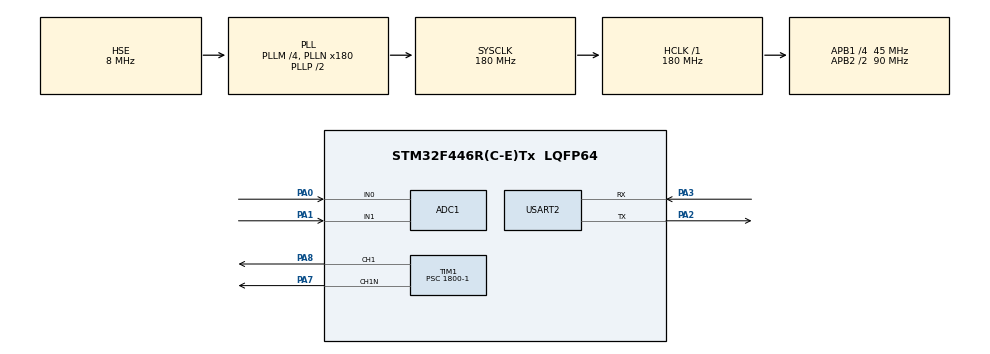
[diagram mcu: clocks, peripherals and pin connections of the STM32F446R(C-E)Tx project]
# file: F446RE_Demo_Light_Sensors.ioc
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ADC1.Channel-0\#ChannelRegularConversion=ADC_CHANNEL_0
ADC1.Channel-1\#ChannelRegularConversion=ADC_CHANNEL_1
ADC1.DMAContinuousRequests=ENABLE
ADC1.EOCSelection=ADC_EOC_SEQ_CONV
ADC1.ExternalTrigConv=ADC_EXTERNALTRIGCONV_T2_TRGO
ADC1.NbrOfConversion=2
ADC1.NbrOfConversionFlag=1
ADC1.Rank-0\#ChannelRegularConversion=1
ADC1.Rank-1\#ChannelRegularConversion=2
ADC1.SamplingTime-0\#ChannelRegularConversion=ADC_SAMPLETIME_3CYCLES
ADC1.SamplingTime-1\#ChannelRegularConversion=ADC_SAMPLETIME_3CYCLES
ADC1.master=1
Dma.ADC1.0.Direction=DMA_PERIPH_TO_MEMORY
Dma.ADC1.0.FIFOMode=DMA_FIFOMODE_DISABLE
Dma.ADC1.0.Instance=DMA2_Stream0
Dma.ADC1.0.MemDataAlignment=DMA_MDATAALIGN_HALFWORD
Dma.ADC1.0.MemInc=DMA_MINC_ENABLE
Dma.ADC1.0.Mode=DMA_CIRCULAR
Dma.ADC1.0.PeriphDataAlignment=DMA_PDATAALIGN_HALFWORD
Dma.ADC1.0.PeriphInc=DMA_PINC_DISABLE
Dma.ADC1.0.Priority=DMA_PRIORITY_LOW
Dma.Request0=ADC1
Dma.Request1=TIM1_CH1
Dma.Request2=USART2_TX
Dma.TIM1_CH1.1.Direction=DMA_MEMORY_TO_PERIPH
Dma.TIM1_CH1.1.FIFOMode=DMA_FIFOMODE_DISABLE
Dma.TIM1_CH1.1.Instance=DMA2_Stream1
Dma.TIM1_CH1.1.MemDataAlignment=DMA_MDATAALIGN_HALFWORD
Dma.TIM1_CH1.1.MemInc=DMA_MINC_ENABLE
Dma.TIM1_CH1.1.Mode=DMA_CIRCULAR
Dma.TIM1_CH1.1.PeriphDataAlignment=DMA_PDATAALIGN_HALFWORD
Dma.TIM1_CH1.1.PeriphInc=DMA_PINC_DISABLE
Dma.TIM1_CH1.1.Priority=DMA_PRIORITY_LOW
Dma.USART2_TX.2.Direction=DMA_MEMORY_TO_PERIPH
Dma.USART2_TX.2.FIFOMode=DMA_FIFOMODE_DISABLE
Dma.USART2_TX.2.Instance=DMA1_Stream6
Dma.USART2_TX.2.MemDataAlignment=DMA_MDATAALIGN_BYTE
Dma.USART2_TX.2.MemInc=DMA_MINC_ENABLE
Dma.USART2_TX.2.Mode=DMA_CIRCULAR
Dma.USART2_TX.2.PeriphDataAlignment=DMA_PDATAALIGN_BYTE
Dma.USART2_TX.2.PeriphInc=DMA_PINC_DISABLE
Dma.USART2_TX.2.Priority=DMA_PRIORITY_LOW
Mcu.Family=STM32F4
Mcu.Name=STM32F446R(C-E)Tx
Mcu.Package=LQFP64
NVIC.ADC_IRQn=true\:0\:0\:false\:false\:true\:true\:true\:true
NVIC.DMA1_Stream6_IRQn=true\:0\:0\:false\:false\:true\:false\:true\:true
NVIC.DMA2_Stream0_IRQn=true\:0\:0\:false\:false\:true\:false\:true\:true
NVIC.DMA2_Stream1_IRQn=true\:0\:0\:false\:false\:true\:false\:true\:true
NVIC.PriorityGroup=NVIC_PRIORITYGROUP_4
NVIC.TIM2_IRQn=true\:0\:0\:false\:false\:true\:true\:true\:true
NVIC.USART2_IRQn=true\:0\:0\:false\:false\:true\:true\:true\:true
PA0-WKUP.Signal=ADCx_IN0
PA1.Signal=ADCx_IN1
PA13.Mode=Serial_Wire
PA13.Signal=SYS_JTMS-SWDIO
PA14.Mode=Serial_Wire
PA14.Signal=SYS_JTCK-SWCLK
PA2.Mode=Asynchronous
PA2.Signal=USART2_TX
PA3.Mode=Asynchronous
PA3.Signal=USART2_RX
PA7.Mode=PWM Generation1 CH1 CH1N
PA7.Signal=TIM1_CH1N
PA8.Signal=S_TIM1_CH1
PH0-OSC_IN.Mode=HSE-External-Clock-Source
PH0-OSC_IN.Signal=RCC_OSC_IN
PH1-OSC_OUT.Mode=HSE-External-Clock-Source
PH1-OSC_OUT.Signal=RCC_OSC_OUT
ProjectManager.HeapSize=0x200
ProjectManager.StackSize=0x400
ProjectManager.TargetToolchain=STM32CubeIDE
RCC.AHBFreq_Value=180000000
RCC.APB1CLKDivider=RCC_HCLK_DIV4
RCC.APB1Freq_Value=45000000
RCC.APB1TimFreq_Value=90000000
RCC.APB2CLKDivider=RCC_HCLK_DIV2
RCC.APB2Freq_Value=90000000
RCC.APB2TimFreq_Value=180000000
RCC.CortexFreq_Value=180000000
RCC.HCLKFreq_Value=180000000
RCC.HSE_VALUE=8000000
RCC.PLLM=4
RCC.PLLN=180
RCC.PLLSourceVirtual=RCC_PLLSOURCE_HSE
RCC.SYSCLKFreq_VALUE=180000000
RCC.SYSCLKSource=RCC_SYSCLKSOURCE_PLLCLK
RCC.USBFreq_Value=180000000
RCC.VCOOutputFreq_Value=360000000
SH.ADCx_IN0.0=ADC1_IN0,IN0
SH.ADCx_IN1.0=ADC1_IN1,IN1
SH.S_TIM1_CH1.0=TIM1_CH1,PWM Generation1 CH1 CH1N
TIM1.Channel-PWM\ Generation1\ CH1\ CH1N=TIM_CHANNEL_1
TIM1.OCNPolarity_1=TIM_OCNPOLARITY_HIGH
TIM1.Period=1000-1
TIM1.Prescaler=1800-1
TIM2.Period=1000-1
TIM2.Prescaler=900-1
TIM2.TIM_MasterOutputTrigger=TIM_TRGO_UPDATE
USART2.VirtualMode=VM_ASYNC
VP_TIM1_VS_ClockSourceINT.Mode=Internal
VP_TIM2_VS_ClockSourceINT.Mode=Internal
board=custom

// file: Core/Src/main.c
/* USER CODE BEGIN Header */
/**
  ******************************************************************************
  * @file           : main.c
  * @brief          : Main program body
  ******************************************************************************
  * @attention
  *
  * Copyright (c) 2026 STMicroelectronics.
  * All rights reserved.
  *
  * This software is licensed under terms that can be found in the LICENSE file
  * in the root directory of this software component.
  * If no LICENSE file comes with this software, it is provided AS-IS.
  *
  ******************************************************************************
  */
/* USER CODE END Header */
#include "main.h"

/* USER CODE BEGIN Includes */
#include <stdio.h>
#include <string.h>
/* USER CODE END Includes */

/* USER CODE BEGIN PD */
#define ADC_BUF_LEN 40	//set adc buffer size
/* USER CODE END PD */

ADC_HandleTypeDef hadc1;
DMA_HandleTypeDef hdma_adc1;

TIM_HandleTypeDef htim1;
TIM_HandleTypeDef htim2;
DMA_HandleTypeDef hdma_tim1_ch1;

UART_HandleTypeDef huart2;
DMA_HandleTypeDef hdma_usart2_tx;

void SystemClock_Config(void);
static void MX_GPIO_Init(void);
static void MX_DMA_Init(void);
static void MX_ADC1_Init(void);
static void MX_TIM2_Init(void);
static void MX_TIM1_Init(void);
static void MX_USART2_UART_Init(void);

/* USER CODE BEGIN 0 */

// Pre-computed 512-point sine wave scaled for ARR = 1000
const uint16_t SINE_WAVE_LUT_512[512] = {
     500,  506,  512,  518,  525,  531,  537,  543,  549,  555,  561,  567,  573,  579,  585,  592,
     598,  604,  610,  616,  621,  627,  633,  639,  645,  651,  657,  663,  668,  674,  680,  686,
     691,  697,  703,  708,  714,  719,  725,  730,  736,  741,  746,  752,  757,  762,  767,  773,
     778,  783,  788,  793,  798,  803,  808,  812,  817,  822,  827,  831,  836,  840,  845,  849,
     854,  858,  862,  866,  870,  875,  879,  883,  887,  890,  894,  898,  902,  905,  909,  912,
     916,  919,  922,  926,  929,  932,  935,  938,  941,  944,  947,  949,  952,  955,  957,  960,
     962,  964,  966,  969,  971,  973,  975,  977,  978,  980,  982,  983,  985,  986,  988,  989,
     990,  992,  993,  994,  995,  995,  996,  997,  998,  998,  999,  999,  999, 1000, 1000, 1000,
    1000, 1000, 1000, 1000,  999,  999,  999,  998,  998,  997,  996,  995,  995,  994,  993,  992,
     990,  989,  988,  986,  985,  983,  982,  980,  978,  977,  975,  973,  971,  969,  966,  964,
     962,  960,  957,  955,  952,  949,  947,  944,  941,  938,  935,  932,  929,  926,  922,  919,
     916,  912,  909,  905,  902,  898,  894,  890,  887,  883,  879,  875,  870,  866,  862,  858,
     854,  849,  845,  840,  836,  831,  827,  822,  817,  812,  808,  803,  798,  793,  788,  783,
     778,  773,  767,  762,  757,  752,  746,  741,  736,  730,  725,  719,  714,  708,  703,  697,
     691,  686,  680,  674,  668,  663,  657,  651,  645,  639,  633,  627,  621,  616,  610,  604,
     598,  592,  585,  579,  573,  567,  561,  555,  549,  543,  537,  531,  525,  518,  512,  506,
     500,  494,  488,  482,  475,  469,  463,  457,  451,  445,  439,  433,  427,  421,  415,  408,
     402,  396,  390,  384,  379,  373,  367,  361,  355,  349,  343,  337,  332,  326,  320,  314,
     309,  303,  297,  292,  286,  281,  275,  270,  264,  259,  254,  248,  243,  238,  233,  227,
     222,  217,  212,  207,  202,  197,  192,  188,  183,  178,  173,  169,  164,  160,  155,  151,
     146,  142,  138,  134,  130,  125,  121,  117,  113,  110,  106,  102,   98,   95,   91,   88,
      84,   81,   78,   74,   71,   68,   65,   62,   59,   56,   53,   51,   48,   45,   43,   40,
      38,   36,   34,   31,   29,   27,   25,   23,   22,   20,   18,   17,   15,   14,   12,   11,
      10,    8,    7,    6,    5,    5,    4,    3,    2,    2,    1,    1,    1,    0,    0,    0,
       0,    0,    0,    0,    1,    1,    1,    2,    2,    3,    4,    5,    5,    6,    7,    8,
      10,   11,   12,   14,   15,   17,   18,   20,   22,   23,   25,   27,   29,   31,   34,   36,
      38,   40,   43,   45,   48,   51,   53,   56,   59,   62,   65,   68,   71,   74,   78,   81,
      84,   88,   91,   95,   98,  102,  106,  110,  113,  117,  121,  125,  130,  134,  138,  142,
     146,  151,  155,  160,  164,  169,  173,  178,  183,  188,  192,  197,  202,  207,  212,  217,
     222,  227,  233,  238,  243,  248,  254,  259,  264,  270,  275,  281,  286,  292,  297,  303,
     309,  314,  320,  326,  332,  337,  343,  349,  355,  361,  367,  373,  379,  384,  390,  396,
     402,  408,  415,  421,  427,  433,  439,  445,  451,  457,  463,  469,  475,  482,  488,  494
};

uint16_t ADCBatchData[ADC_BUF_LEN];	//store the 2 channels raw ADC data in a batch of 20 samples (40 elements)
char uartTxBuffer[256];	//store the formatted ADC data to transmit via uart, 256 bytes big enough to temporarily hold the formatted 10 samples

//helper function to format the raw adc data and store into uartTxBuffer, then transmit the half buffer
//param: half of the adc buffer = ADCBatchData[0] or ADCBatchData[20]
void processADCData(uint16_t* half_buffer)
{

    uartTxBuffer[0] = '\0';	//Clear the tx buffer
    char temp[32];	//temp buffer to format and move ADC data into the main tx buffer

    //format and load the adc data to the main tx buffer
    for(int i = 0; i < (ADC_BUF_LEN / 2); i += 2)
    {
    	//load raw ADC data
        uint16_t adcDataC1 = half_buffer[i];		//channel 1
        uint16_t adcDataC2 = half_buffer[i + 1];	//channel 2

        //format the datas and store to temp, then temp cocantenate it to the main tx buffer
        sprintf(temp, "%u, %u \r\n", adcDataC1, adcDataC2);
        strcat(uartTxBuffer, temp);	//strcat() appends a copy of one string to the end of another
    }

    //transmit the formatted data
    HAL_UART_Transmit_DMA(&huart2, (uint8_t*)uartTxBuffer, strlen(uartTxBuffer));
}

void HAL_ADC_ConvHalfCpltCallback(ADC_HandleTypeDef *hadc)
{
	processADCData(&ADCBatchData[0]);	//process and tx first half of the ADC data
}

void HAL_ADC_ConvCpltCallback(ADC_HandleTypeDef *hadc)
{
	processADCData(&ADCBatchData[ADC_BUF_LEN / 2]);	//process and tx 2nd half of the ADC data
}

/* USER CODE END 0 */

int main(void)
{

  /* MCU Configuration--------------------------------------------------------*/

  /* Reset of all peripherals, Initializes the Flash interface and the Systick. */
  HAL_Init();

  /* Configure the system clock */
  SystemClock_Config();

  /* Initialize all configured peripherals */
  MX_GPIO_Init();
  MX_DMA_Init();
  MX_ADC1_Init();
  MX_TIM2_Init();
  MX_TIM1_Init();
  MX_USART2_UART_Init();
  /* USER CODE BEGIN 2 */

  HAL_TIM_Base_Start(&htim2);	//start timer2 as per configured
  HAL_ADC_Start_DMA(&hadc1, (uint32_t *)ADCBatchData, ADC_BUF_LEN);	//ADC sampling rate = 100Hz, uart baudrate 115200

  //generate sine wave blue led f_sine = 100Hz/512 = 0.195Hz, tim1 freq = 100 Hz
  HAL_TIM_PWM_Start_DMA(&htim1, TIM_CHANNEL_1, (uint32_t *)SINE_WAVE_LUT_512, 512);
  //generate cos wave via Complementary Output "PWM Generation CH1 CH1N" mode
  HAL_TIMEx_PWMN_Start(&htim1, TIM_CHANNEL_1);

  /* USER CODE END 2 */

  /* Infinite loop */
  while (1)
  {

  }
}

void SystemClock_Config(void)
{
  RCC_OscInitTypeDef RCC_OscInitStruct = {0};
  RCC_ClkInitTypeDef RCC_ClkInitStruct = {0};

  /** Configure the main internal regulator output voltage
  */
  __HAL_RCC_PWR_CLK_ENABLE();
  __HAL_PWR_VOLTAGESCALING_CONFIG(PWR_REGULATOR_VOLTAGE_SCALE1);

  /** Initializes the RCC Oscillators according to the specified parameters
  * in the RCC_OscInitTypeDef structure.
  */
  RCC_OscInitStruct.OscillatorType = RCC_OSCILLATORTYPE_HSE;
  RCC_OscInitStruct.HSEState = RCC_HSE_BYPASS;
  RCC_OscInitStruct.PLL.PLLState = RCC_PLL_ON;
  RCC_OscInitStruct.PLL.PLLSource = RCC_PLLSOURCE_HSE;
  RCC_OscInitStruct.PLL.PLLM = 4;
  RCC_OscInitStruct.PLL.PLLN = 180;
  RCC_OscInitStruct.PLL.PLLP = RCC_PLLP_DIV2;
  RCC_OscInitStruct.PLL.PLLQ = 2;
  RCC_OscInitStruct.PLL.PLLR = 2;
  if (HAL_RCC_OscConfig(&RCC_OscInitStruct) != HAL_OK)
  {
    Error_Handler();
  }

  /** Activate the Over-Drive mode
  */
  if (HAL_PWREx_EnableOverDrive() != HAL_OK)
  {
    Error_Handler();
  }

  /** Initializes the CPU, AHB and APB buses clocks
  */
  RCC_ClkInitStruct.ClockType = RCC_CLOCKTYPE_HCLK|RCC_CLOCKTYPE_SYSCLK
                              |RCC_CLOCKTYPE_PCLK1|RCC_CLOCKTYPE_PCLK2;
  RCC_ClkInitStruct.SYSCLKSource = RCC_SYSCLKSOURCE_PLLCLK;
  RCC_ClkInitStruct.AHBCLKDivider = RCC_SYSCLK_DIV1;
  RCC_ClkInitStruct.APB1CLKDivider = RCC_HCLK_DIV4;
  RCC_ClkInitStruct.APB2CLKDivider = RCC_HCLK_DIV2;

  if (HAL_RCC_ClockConfig(&RCC_ClkInitStruct, FLASH_LATENCY_5) != HAL_OK)
  {
    Error_Handler();
  }
}

static void MX_ADC1_Init(void)
{

  ADC_ChannelConfTypeDef sConfig = {0};

  /** Configure the global features of the ADC (Clock, Resolution, Data Alignment and number of conversion)
  */
  hadc1.Instance = ADC1;
  hadc1.Init.ClockPrescaler = ADC_CLOCK_SYNC_PCLK_DIV4;
  hadc1.Init.Resolution = ADC_RESOLUTION_12B;
  hadc1.Init.ScanConvMode = ENABLE;
  hadc1.Init.ContinuousConvMode = DISABLE;
  hadc1.Init.DiscontinuousConvMode = DISABLE;
  hadc1.Init.ExternalTrigConvEdge = ADC_EXTERNALTRIGCONVEDGE_RISING;
  hadc1.Init.ExternalTrigConv = ADC_EXTERNALTRIGCONV_T2_TRGO;
  hadc1.Init.DataAlign = ADC_DATAALIGN_RIGHT;
  hadc1.Init.NbrOfConversion = 2;
  hadc1.Init.DMAContinuousRequests = ENABLE;
  hadc1.Init.EOCSelection = ADC_EOC_SEQ_CONV;
  if (HAL_ADC_Init(&hadc1) != HAL_OK)
  {
    Error_Handler();
  }

  /** Configure for the selected ADC regular channel its corresponding rank in the sequencer and its sample time.
  */
  sConfig.Channel = ADC_CHANNEL_0;
  sConfig.Rank = 1;
  sConfig.SamplingTime = ADC_SAMPLETIME_3CYCLES;
  if (HAL_ADC_ConfigChannel(&hadc1, &sConfig) != HAL_OK)
  {
    Error_Handler();
  }

  /** Configure for the selected ADC regular channel its corresponding rank in the sequencer and its sample time.
  */
  sConfig.Channel = ADC_CHANNEL_1;
  sConfig.Rank = 2;
  if (HAL_ADC_ConfigChannel(&hadc1, &sConfig) != HAL_OK)
  {
    Error_Handler();
  }

}

static void MX_TIM1_Init(void)
{

  TIM_ClockConfigTypeDef sClockSourceConfig = {0};
  TIM_MasterConfigTypeDef sMasterConfig = {0};
  TIM_OC_InitTypeDef sConfigOC = {0};
  TIM_BreakDeadTimeConfigTypeDef sBreakDeadTimeConfig = {0};

  htim1.Instance = TIM1;
  htim1.Init.Prescaler = 1800-1;
  htim1.Init.CounterMode = TIM_COUNTERMODE_UP;
  htim1.Init.Period = 1000-1;
  htim1.Init.ClockDivision = TIM_CLOCKDIVISION_DIV1;
  htim1.Init.RepetitionCounter = 0;
  htim1.Init.AutoReloadPreload = TIM_AUTORELOAD_PRELOAD_DISABLE;
  if (HAL_TIM_Base_Init(&htim1) != HAL_OK)
  {
    Error_Handler();
  }
  sClockSourceConfig.ClockSource = TIM_CLOCKSOURCE_INTERNAL;
  if (HAL_TIM_ConfigClockSource(&htim1, &sClockSourceConfig) != HAL_OK)
  {
    Error_Handler();
  }
  if (HAL_TIM_PWM_Init(&htim1) != HAL_OK)
  {
    Error_Handler();
  }
  sMasterConfig.MasterOutputTrigger = TIM_TRGO_RESET;
  sMasterConfig.MasterSlaveMode = TIM_MASTERSLAVEMODE_DISABLE;
  if (HAL_TIMEx_MasterConfigSynchronization(&htim1, &sMasterConfig) != HAL_OK)
  {
    Error_Handler();
  }
  sConfigOC.OCMode = TIM_OCMODE_PWM1;
  sConfigOC.Pulse = 0;
  sConfigOC.OCPolarity = TIM_OCPOLARITY_HIGH;
  sConfigOC.OCNPolarity = TIM_OCNPOLARITY_HIGH;
  sConfigOC.OCFastMode = TIM_OCFAST_DISABLE;
  sConfigOC.OCIdleState = TIM_OCIDLESTATE_RESET;
  sConfigOC.OCNIdleState = TIM_OCNIDLESTATE_RESET;
  if (HAL_TIM_PWM_ConfigChannel(&htim1, &sConfigOC, TIM_CHANNEL_1) != HAL_OK)
  {
    Error_Handler();
  }
  sBreakDeadTimeConfig.OffStateRunMode = TIM_OSSR_DISABLE;
  sBreakDeadTimeConfig.OffStateIDLEMode = TIM_OSSI_DISABLE;
  sBreakDeadTimeConfig.LockLevel = TIM_LOCKLEVEL_OFF;
  sBreakDeadTimeConfig.DeadTime = 0;
  sBreakDeadTimeConfig.BreakState = TIM_BREAK_DISABLE;
  sBreakDeadTimeConfig.BreakPolarity = TIM_BREAKPOLARITY_HIGH;
  sBreakDeadTimeConfig.AutomaticOutput = TIM_AUTOMATICOUTPUT_DISABLE;
  if (HAL_TIMEx_ConfigBreakDeadTime(&htim1, &sBreakDeadTimeConfig) != HAL_OK)
  {
    Error_Handler();
  }
  HAL_TIM_MspPostInit(&htim1);

}

static void MX_TIM2_Init(void)
{

  TIM_ClockConfigTypeDef sClockSourceConfig = {0};
  TIM_MasterConfigTypeDef sMasterConfig = {0};

  htim2.Instance = TIM2;
  htim2.Init.Prescaler = 900-1;
  htim2.Init.CounterMode = TIM_COUNTERMODE_UP;
  htim2.Init.Period = 1000-1;
  htim2.Init.ClockDivision = TIM_CLOCKDIVISION_DIV1;
  htim2.Init.AutoReloadPreload = TIM_AUTORELOAD_PRELOAD_DISABLE;
  if (HAL_TIM_Base_Init(&htim2) != HAL_OK)
  {
    Error_Handler();
  }
  sClockSourceConfig.ClockSource = TIM_CLOCKSOURCE_INTERNAL;
  if (HAL_TIM_ConfigClockSource(&htim2, &sClockSourceConfig) != HAL_OK)
  {
    Error_Handler();
  }
  sMasterConfig.MasterOutputTrigger = TIM_TRGO_UPDATE;
  sMasterConfig.MasterSlaveMode = TIM_MASTERSLAVEMODE_DISABLE;
  if (HAL_TIMEx_MasterConfigSynchronization(&htim2, &sMasterConfig) != HAL_OK)
  {
    Error_Handler();
  }

}

static void MX_USART2_UART_Init(void)
{

  huart2.Instance = USART2;
  huart2.Init.BaudRate = 115200;
  huart2.Init.WordLength = UART_WORDLENGTH_8B;
  huart2.Init.StopBits = UART_STOPBITS_1;
  huart2.Init.Parity = UART_PARITY_NONE;
  huart2.Init.Mode = UART_MODE_TX_RX;
  huart2.Init.HwFlowCtl = UART_HWCONTROL_NONE;
  huart2.Init.OverSampling = UART_OVERSAMPLING_16;
  if (HAL_UART_Init(&huart2) != HAL_OK)
  {
    Error_Handler();
  }

}

static void MX_DMA_Init(void)
{

  /* DMA controller clock enable */
  __HAL_RCC_DMA2_CLK_ENABLE();
  __HAL_RCC_DMA1_CLK_ENABLE();

  /* DMA interrupt init */
  /* DMA1_Stream6_IRQn interrupt configuration */
  HAL_NVIC_SetPriority(DMA1_Stream6_IRQn, 0, 0);
  HAL_NVIC_EnableIRQ(DMA1_Stream6_IRQn);
  /* DMA2_Stream0_IRQn interrupt configuration */
  HAL_NVIC_SetPriority(DMA2_Stream0_IRQn, 0, 0);
  HAL_NVIC_EnableIRQ(DMA2_Stream0_IRQn);
  /* DMA2_Stream1_IRQn interrupt configuration */
  HAL_NVIC_SetPriority(DMA2_Stream1_IRQn, 0, 0);
  HAL_NVIC_EnableIRQ(DMA2_Stream1_IRQn);

}

static void MX_GPIO_Init(void)
{
  GPIO_InitTypeDef GPIO_InitStruct = {0};

  /* GPIO Ports Clock Enable */
  __HAL_RCC_GPIOH_CLK_ENABLE();
  __HAL_RCC_GPIOA_CLK_ENABLE();

  /*Configure GPIO pin Output Level */
  HAL_GPIO_WritePin(GPIOA, GPIO_PIN_5, GPIO_PIN_RESET);

  /*Configure GPIO pin : PA5 */
  GPIO_InitStruct.Pin = GPIO_PIN_5;
  GPIO_InitStruct.Mode = GPIO_MODE_OUTPUT_PP;
  GPIO_InitStruct.Pull = GPIO_NOPULL;
  GPIO_InitStruct.Speed = GPIO_SPEED_FREQ_LOW;
  HAL_GPIO_Init(GPIOA, &GPIO_InitStruct);

}

void Error_Handler(void)
{
  __disable_irq();
  while (1)
  {
  }
}
